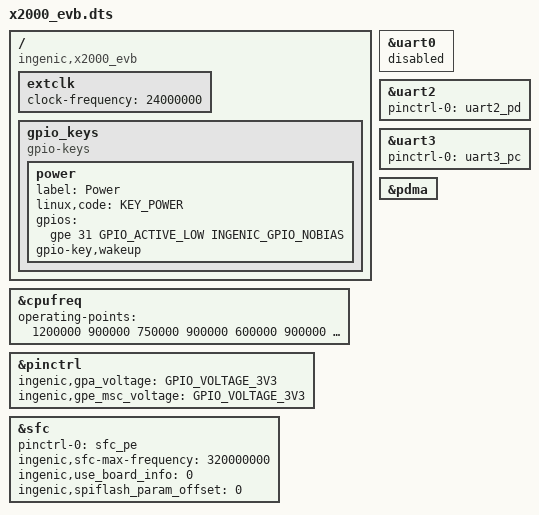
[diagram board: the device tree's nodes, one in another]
/dts-v1/;

#include <dt-bindings/input/input.h>
#include <dt-bindings/interrupt-controller/irq.h>
#include <generated/autoconf.h>

#include "x2000-v12.dtsi"


/ {
	compatible = "ingenic,x2000_evb", "ingenic,x2000-v12";
};

&uart0 {
    status = "disable";
};

&uart2 {
	status = "okay";
	pinctrl-names = "default";
	pinctrl-0 = <&uart2_pd>;
};

&uart3 {
	status = "okay";
	pinctrl-names = "default";
	pinctrl-0 = <&uart3_pc>;
};

&cpufreq {
	status = "okay";
	operating-points = <
		/*KHZ uV */
		1200000	900000
		750000	900000
		600000	900000
		500000	900000
		400000	900000
		375000	900000
		300000	900000
		200000	900000
			>;

};

&pinctrl {
	ingenic,gpa_voltage = <GPIO_VOLTAGE_3V3>;
	ingenic,gpe_msc_voltage = <GPIO_VOLTAGE_3V3>;
};

&pdma {
	status = "okay";
};

&sfc {
	status = "okay";
	pinctrl-names = "default";
	pinctrl-0 = <&sfc_pe>;
	ingenic,sfc-max-frequency = <320000000>;
	ingenic,use_board_info      = /bits/ 8 <0>;
	ingenic,spiflash_param_offset = <0>;
};

/ {

	extclk: extclk {
		clock-frequency = <24000000>;
	};

	gpio_keys: gpio_keys {
		   compatible = "gpio-keys";

		   power {
			   label = "Power";
			   linux,code = <KEY_POWER>;
			   gpios = <&gpe 31 GPIO_ACTIVE_LOW INGENIC_GPIO_NOBIAS>;
			   gpio-key,wakeup;
		   };
	   };
};
